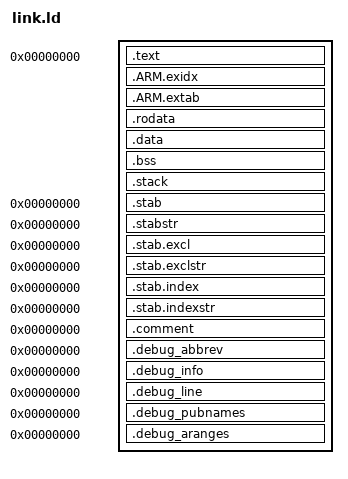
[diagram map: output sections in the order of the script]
OUTPUT_FORMAT("elf32-littlearm", "elf32-bigarm", "elf32-littlearm")
OUTPUT_ARCH(arm)
ENTRY(_start)

STACK_UND_SIZE = 0x10000;
STACK_ABT_SIZE = 0x10000;
STACK_IRQ_SIZE = 0x10000;
STACK_FIQ_SIZE = 0x10000;
STACK_SRV_SIZE = 0x40000;

SECTIONS
{
	. = 0x00000000;

	.text :
	{
		PROVIDE(__image_start = .);
		PROVIDE(__text_start = .);
		PROVIDE(__spl_start = .);
		spl/src/start.o (.text*)
		*(.text*)
		PROVIDE(__spl_end = .);
		*(.init.text)
		*(.exit.text)
		*(.glue*)
		*(.note.gnu.build-id)
		PROVIDE(__text_end = .);
	}
	PROVIDE(__spl_size = __spl_end - __spl_start);

	.ARM.exidx ALIGN(8) :
	{
		PROVIDE (__exidx_start = .);
		*(.ARM.exidx*)
		PROVIDE (__exidx_end = .);
	}

	.ARM.extab ALIGN(8) :
	{
		PROVIDE (__extab_start = .);
		*(.ARM.extab*)
		PROVIDE (__extab_end = .);
	}

	.rodata ALIGN(8) :
	{
		PROVIDE(__rodata_start = .);
		*(SORT_BY_ALIGNMENT(SORT_BY_NAME(.rodata*)))
		PROVIDE(__rodata_end = .);
	}

	.data ALIGN(8) :
	{
		PROVIDE(__data_start = .);
		*(.data*)
		. = ALIGN(8);
  		PROVIDE(__data_end = .);
		PROVIDE(__image_end = .);
	}

	.bss ALIGN(8) (NOLOAD) :
	{
		PROVIDE(__bss_start = .);
		*(.bss*)
		*(.sbss*)
		*(COMMON)
		. = ALIGN(8);
		PROVIDE(__bss_end = .);
	}

	.stack ALIGN(8) (NOLOAD) :
	{
		PROVIDE(__stack_start = .);
		PROVIDE(__stack_und_start = .);
		. += STACK_UND_SIZE;
		PROVIDE(__stack_und_end = .);
		. = ALIGN(8);
		PROVIDE(__stack_abt_start = .);
		. += STACK_ABT_SIZE;
		PROVIDE(__stack_abt_end = .);
		. = ALIGN(8);
		PROVIDE(__stack_irq_start = .);
		. += STACK_IRQ_SIZE;
		PROVIDE(__stack_irq_end = .);
		. = ALIGN(8);
		PROVIDE(__stack_fiq_start = .);
		. += STACK_FIQ_SIZE;
		PROVIDE(__stack_fiq_end = .);
		. = ALIGN(8);
		PROVIDE(__stack_srv_start = .);
		. += STACK_SRV_SIZE;
		PROVIDE(__stack_srv_end = .);
		. = ALIGN(8);
		PROVIDE(__stack_end = .);
	}

	.stab 0 : { *(.stab) }
	.stabstr 0 : { *(.stabstr) }
	.stab.excl 0 : { *(.stab.excl) }
	.stab.exclstr 0 : { *(.stab.exclstr) }
	.stab.index 0 : { *(.stab.index) }
	.stab.indexstr 0 : { *(.stab.indexstr) }
	.comment 0 : { *(.comment) }
	.debug_abbrev 0 : { *(.debug_abbrev) }
	.debug_info 0 : { *(.debug_info) }
	.debug_line 0 : { *(.debug_line) }
	.debug_pubnames 0 : { *(.debug_pubnames) }
	.debug_aranges 0 : { *(.debug_aranges) }
}
